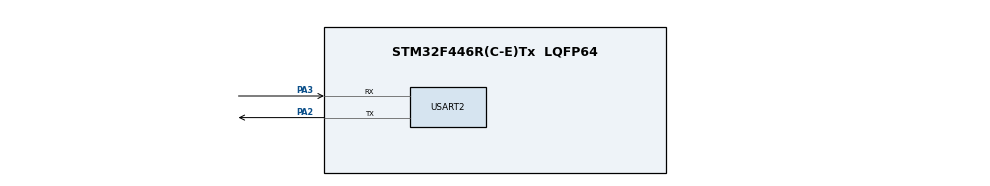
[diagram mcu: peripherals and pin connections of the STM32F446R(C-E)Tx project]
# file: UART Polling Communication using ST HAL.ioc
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Mcu.Family=STM32F4
Mcu.Name=STM32F446R(C-E)Tx
Mcu.Package=LQFP64
NVIC.PriorityGroup=NVIC_PRIORITYGROUP_4
PA2.Mode=Asynchronous
PA2.Signal=USART2_TX
PA3.Mode=Asynchronous
PA3.Signal=USART2_RX
ProjectManager.HeapSize=0x200
ProjectManager.StackSize=0x400
ProjectManager.TargetToolchain=STM32CubeIDE
RCC.CortexFreq_Value=16000000
RCC.USBFreq_Value=96000000
RCC.VCOOutputFreq_Value=192000000
USART2.VirtualMode=VM_ASYNC
board=custom

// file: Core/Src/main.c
/* USER CODE BEGIN Header */
/**
  ******************************************************************************
  * @file           : main.c
  * @brief          : Main program body
  ******************************************************************************
  * @attention
  *
  * Copyright (c) 2025 STMicroelectronics.
  * All rights reserved.
  *
  * This software is licensed under terms that can be found in the LICENSE file
  * in the root directory of this software component.
  * If no LICENSE file comes with this software, it is provided AS-IS.
  *
  ******************************************************************************
  */
/* USER CODE END Header */
#include "main.h"

/* USER CODE BEGIN Includes */
#include <stdio.h>
#include <string.h>
#include <stdlib.h>
#include  "stm32f4xx_hal.h"

#define WELCOME_MSG  " Welcome to STM32 Menu!\n"
#define MAIN_MENU " This is the main menu : \n"

/* USER CODE END Includes */

UART_HandleTypeDef huart2;

void SystemClock_Config(void);
static void MX_GPIO_Init(void);
static void MX_USART2_UART_Init(void);

/* USER CODE BEGIN 0 */
void printMyWelcomeMSG(void)
{
	    HAL_UART_Transmit(&huart2, (uint8_t *) "\033[0;0H", strlen("\033[0;0H"), HAL_MAX_DELAY);
	    HAL_UART_Transmit(&huart2, (uint8_t *)"\033[23", strlen("\033[23"),HAL_MAX_DELAY);           /*UART2 Handle huart*/
	    HAL_UART_Transmit(&huart2, (uint8_t *)WELCOME_MSG, strlen(WELCOME_MSG), HAL_MAX_DELAY);
	    HAL_UART_Transmit(&huart2, (uint8_t *)MAIN_MENU, strlen(MAIN_MENU), HAL_MAX_DELAY);
}

uint8_t userNumber(void)
{
	           char number[1];
               HAL_UART_Transmit(&huart2, (uint8_t *) " Please enter a number : \n", strlen("Please enter a number : \n"), HAL_MAX_DELAY);
               HAL_UART_Receive(&huart2, (uint8_t *)number, 1, HAL_MAX_DELAY);
               return atoi(number);
}

uint8_t processNumber(uint8_t userOption)
{
	          char msg[30];
              if(userOption > 3 ||  userOption <= 0)
              {
            	          HAL_UART_Transmit(&huart2, (uint8_t *)"WRONG OPTION!\n", strlen("WRONG OPTION!\n"), HAL_MAX_DELAY);
            	          return 0;
              }

              sprintf(msg, "%d", userOption);
              HAL_UART_Transmit(&huart2, (uint8_t *)msg, 1, HAL_MAX_DELAY);

              switch(userOption)
              {
                           case 1:
                        	     HAL_GPIO_TogglePin(GPIOA, GPIO_PIN_5);
                        	     break;
                           case 2:
                    sprintf(msg,  "\r\nUSER BUTTON status: %s", HAL_GPIO_ReadPin(GPIOC, GPIO_PIN_13) == GPIO_PIN_RESET ? "PRESSED" : "RELEASED");
                    HAL_UART_Transmit(&huart2, (uint8_t *)msg, strlen(msg), HAL_MAX_DELAY);
                    break;
                           case 3:
                        	     return 2;
              };
              return 1;
}

/* USER CODE END 0 */

int main(void)
{

  /* MCU Configuration--------------------------------------------------------*/

  /* Reset of all peripherals, Initializes the Flash interface and the Systick. */
  HAL_Init();

  /* Configure the system clock */
  SystemClock_Config();

  /* Initialize all configured peripherals */
  MX_GPIO_Init();
  MX_USART2_UART_Init();

  /* USER CODE BEGIN 2 */
  uint8_t opt;

  __HAL_RCC_GPIOA_CLK_ENABLE();
  GPIO_InitTypeDef GPIO_InitStruct = {0};

  GPIO_InitStruct.Pin = GPIO_PIN_5;
  GPIO_InitStruct.Mode = GPIO_MODE_OUTPUT_PP;
  GPIO_InitStruct.Pull = GPIO_NOPULL;
  GPIO_InitStruct.Speed = GPIO_SPEED_FREQ_LOW;
  HAL_GPIO_Init(GPIOA, &GPIO_InitStruct);

  printMessage:
             printMyWelcomeMSG();

  /* USER CODE END 2 */

  /* Infinite loop */
  /* USER CODE BEGIN WHILE */
  while (1)
  {
         opt = userNumber();
         processNumber(opt);
         if(opt == 3)
        	    goto printMessage;
    /* USER CODE END WHILE */

  }
}
/* USER CODE BEGIN 3 */

  /* USER CODE END 3 *

/*
  * @brief System Clock Configuration
  * @retval None
  */
void SystemClock_Config(void)
{
  RCC_OscInitTypeDef RCC_OscInitStruct = {0};
  RCC_ClkInitTypeDef RCC_ClkInitStruct = {0};

  /** Configure the main internal regulator output voltage
  */
  __HAL_RCC_PWR_CLK_ENABLE();
  __HAL_PWR_VOLTAGESCALING_CONFIG(PWR_REGULATOR_VOLTAGE_SCALE3);

  /** Initializes the RCC Oscillators according to the specified parameters
  * in the RCC_OscInitTypeDef structure.
  */
  RCC_OscInitStruct.OscillatorType = RCC_OSCILLATORTYPE_HSI;
  RCC_OscInitStruct.HSIState = RCC_HSI_ON;
  RCC_OscInitStruct.HSICalibrationValue = RCC_HSICALIBRATION_DEFAULT;
  RCC_OscInitStruct.PLL.PLLState = RCC_PLL_NONE;
  if (HAL_RCC_OscConfig(&RCC_OscInitStruct) != HAL_OK)
  {
    Error_Handler();
  }

  /** Initializes the CPU, AHB and APB buses clocks
  */
  RCC_ClkInitStruct.ClockType = RCC_CLOCKTYPE_HCLK|RCC_CLOCKTYPE_SYSCLK
                              |RCC_CLOCKTYPE_PCLK1|RCC_CLOCKTYPE_PCLK2;
  RCC_ClkInitStruct.SYSCLKSource = RCC_SYSCLKSOURCE_HSI;
  RCC_ClkInitStruct.AHBCLKDivider = RCC_SYSCLK_DIV1;
  RCC_ClkInitStruct.APB1CLKDivider = RCC_HCLK_DIV1;
  RCC_ClkInitStruct.APB2CLKDivider = RCC_HCLK_DIV1;

  if (HAL_RCC_ClockConfig(&RCC_ClkInitStruct, FLASH_LATENCY_0) != HAL_OK)
  {
    Error_Handler();
  }
}

static void MX_USART2_UART_Init(void)
{

  huart2.Instance = USART2;
  huart2.Init.BaudRate = 115200;
  huart2.Init.WordLength = UART_WORDLENGTH_8B;
  huart2.Init.StopBits = UART_STOPBITS_1;
  huart2.Init.Parity = UART_PARITY_NONE;
  huart2.Init.Mode = UART_MODE_TX_RX;
  huart2.Init.HwFlowCtl = UART_HWCONTROL_NONE;
  huart2.Init.OverSampling = UART_OVERSAMPLING_16;
  if (HAL_UART_Init(&huart2) != HAL_OK)
  {
    Error_Handler();
  }

}

static void MX_GPIO_Init(void)
{

  /* GPIO Ports Clock Enable */
  __HAL_RCC_GPIOA_CLK_ENABLE();

}

void Error_Handler(void)
{
  __disable_irq();
  while (1)
  {
  }
}
